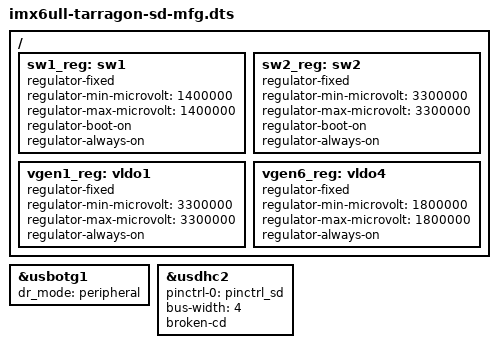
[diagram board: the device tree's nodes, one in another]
#include "imx6ull-tarragon.dtsi"

/ {
	/* Values take from PF3001 datasheet
	 * OTP configuration: A7
	 */
	sw1_reg: sw1 {
		compatible = "regulator-fixed";
		regulator-min-microvolt = <1400000>;
		regulator-max-microvolt = <1400000>;
		regulator-boot-on;
		regulator-always-on;
	};

	sw2_reg: sw2 {
		compatible = "regulator-fixed";
		regulator-min-microvolt = <3300000>;
		regulator-max-microvolt = <3300000>;
		regulator-boot-on;
		regulator-always-on;
	};

	vgen1_reg: vldo1 {
		compatible = "regulator-fixed";
		regulator-min-microvolt = <3300000>;
		regulator-max-microvolt = <3300000>;
		regulator-always-on;
	};

	vgen6_reg: vldo4 {
		compatible = "regulator-fixed";
		regulator-min-microvolt = <1800000>;
		regulator-max-microvolt = <1800000>;
		regulator-always-on;
	};
};

&usbotg1 {
	dr_mode = "peripheral";
	status = "okay";
};

&usdhc2 {
	pinctrl-names = "default";
	pinctrl-0 = <&pinctrl_sd>;
	bus-width = <4>;
	broken-cd;
	status = "okay";
};
